# LKS32MC07x register map
Vendor: Linko Ltd.; Series: LKS32MC07x; File version: 1.0
CPU: CM0 r1p0, little endian, MPU, no FPU, 3 interrupt priority bits
Registers are 32-bit, read-write, reset 0x0 unless marked. A register's access mark holds for its fields unless they carry their own. Offsets are from the block's base; [hi:lo] are bit positions; {n}, {i} and the like mark numbered series.

## MCPWM0 — MCPWM0 registers
Base 0x40010C00
0x00 TH00 — CH0 P 16-bit Threshold Value
  [15:0] TH00 — Channel0 P-side threshold
0x04 TH01 — CH0 N 16-bit Threshold Value
  [15:0] TH01 — Channel0 N-side threshold
0x08 TH10 — CH1 P 16-bit Threshold Value
  [15:0] TH10 — Channel1 P-side threshold
0x0C TH11 — CH1 N 16-bit Threshold Value
  [15:0] TH11 — Channel1 N-side threshold
0x10 TH20 — CH2 P 16-bit Threshold Value
  [15:0] TH20 — Channel2 P-side threshold
0x14 TH21 — CH2 N 16-bit Threshold Value
  [15:0] TH21 — Channel2 N-side threshold
0x18 TH30 — CH3 P 16-bit Threshold Value
  [15:0] TH30 — Channel3 P-side threshold
0x1C TH31 — CH3 N 16-bit Threshold Value
  [15:0] TH31 — Channel3 N-side threshold
0x20 TH40 — CH4 P 16-bit Threshold Value
  [15:0] TH40 — Channel4 P-side threshold
0x24 TH41 — CH4 N 16-bit Threshold Value
  [15:0] TH41 — Channel4 N-side threshold
0x28 TH50 — CH5 P 16-bit Threshold Value
  [15:0] TH50 — Channel5 P-side threshold
0x2C TH51 — CH5 N 16-bit Threshold Value
  [15:0] TH51 — Channel5 N-side threshold
{0x30+4i} TMR{i} reset 0x7FFF (i=0..3) — ADC Trigger time {i}
  [15:0] TMR{i} — ADC Trigger time {i} counter value
0x40 TH0 — Base Counter 0 15-bit Unsigned Threshold Value
  [14:0] TH0 — MCPWM Counter 0 TH
0x44 TH1 — Base Counter 1 15-bit Unsigned Threshold Value
  [14:0] TH1 — MCPWM Counter 1 TH
0x48 CNT0 — Base 0 Counter 16-bit Signed Threshold Value
  [15:0] CNT0 — MCPWM Counter 0 Value
0x4C CNT1 — Base 1 Counter 16-bit Signed Value
  [15:0] CNT1 — MCPWM Counter 1 Value
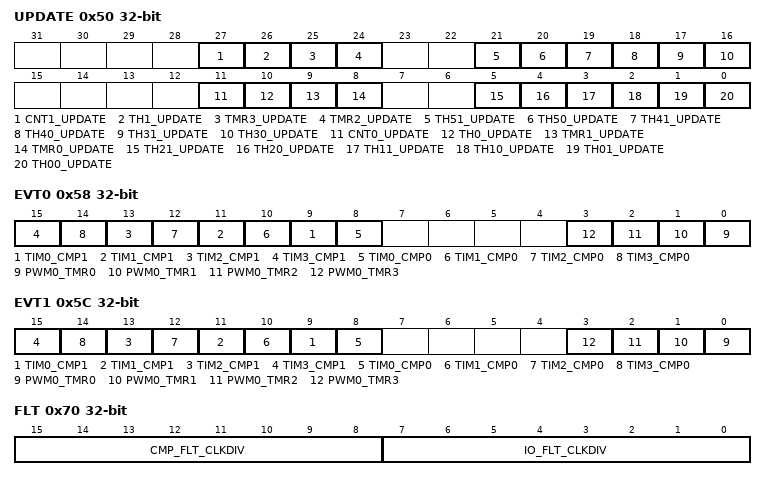
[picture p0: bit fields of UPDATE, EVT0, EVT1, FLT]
0x50 UPDATE wo (reset mask 0xFFFF) — Mask Registers Manual Reload Configuration
  [27] CNT1_UPDATE — Write 1 to trigger CNT1 update immediately
  [26] TH1_UPDATE — Write 1 to trigger TH1 update immediately
  [25] TMR3_UPDATE — Write 1 to trigger TMR3 update immediately
  [24] TMR2_UPDATE — Write 1 to trigger TMR2 update immediately
  [21] TH51_UPDATE — Write 1 to trigger TH51 update immediately
  [20] TH50_UPDATE — Write 1 to trigger TH50 update immediately
  [19] TH41_UPDATE — Write 1 to trigger TH41 update immediately
  [18] TH40_UPDATE — Write 1 to trigger TH40 update immediately
  [17] TH31_UPDATE — Write 1 to trigger TH31 update immediately
  [16] TH30_UPDATE — Write 1 to trigger TH30 update immediately
  [11] CNT0_UPDATE — Write 1 to trigger CNT0 update immediately
  [10] TH0_UPDATE — Write 1 to trigger TH0 update immediately
  [9] TMR1_UPDATE — Write 1 to trigger TMR1 update immediately
  [8] TMR0_UPDATE — Write 1 to trigger TMR0 update immediately
  [5] TH21_UPDATE — Write 1 to trigger TH21 update immediately
  [4] TH20_UPDATE — Write 1 to trigger TH20 update immediately
  [3] TH11_UPDATE — Write 1 to trigger TH11 update immediately
  [2] TH10_UPDATE — Write 1 to trigger TH10 update immediately
  [1] TH01_UPDATE — Write 1 to trigger TH01 update immediately
  [0] TH00_UPDATE — Write 1 to trigger TH00 update immediately
0x54 FCNT — If MCPWM_FAIL012[15] = 1, when fail0/1 occure, store MCPWM_CNT0 to MCPWM_FCNT. If MCPWM_FAIL3[15] = 1, when fail2/3 occure, store MCPWM_CNT0 to MCPWM_FCNT.
  [15:0] FCNT — Counter Value when failure event happens
0x58 EVT0 (reset mask 0xF0F) — MCPWM Base 0 External Trigger Register
  [2n+9] TIM{n}_CMP1 (n=0..3) — TIMER{n} CMP1 base 0 Trigger
  [2n+8] TIM{n}_CMP0 (n=0..3) — TIMER{n} CMP0 base 0 Trigger
  [n] PWM0_TMR{n} (n=0..3) — MCPWM0 TMR{n} base 0 Trigger
0x5C EVT1 (reset mask 0xF0F) — MCPWM Base 1 External Trigger Register
  [2n+9] TIM{n}_CMP1 (n=0..3) — TIMER{n} CMP1 base 1 Trigger
  [2n+8] TIM{n}_CMP0 (n=0..3) — TIMER{n} CMP0 base 1 Trigger
  [n] PWM0_TMR{n} (n=0..3) — MCPWM0 TMR{n} base 1 Trigger
0x60 DTH00 — Channel0/1/2 N Dead Zone Control Register, 10-bit Unsigned
  [9:0] DTH00
0x64 DTH01 — Channel0/1/2 P Dead Zone Control Register, 10-bit Unsigned
  [9:0] DTH01
0x68 DTH10 — Channel3/4/5 N Dead Zone Control Register, 10-bit Unsigned
  [9:0] DTH10
0x6C DTH11 — Channel3/4/5 P Dead Zone Control Register, 10-bit Unsigned
  [9:0] DTH11
0x70 FLT — FAIL signal filter config
  [15:8] CMP_FLT_CLKDIV — Clock Source is System Clock, Divide Range is 1 to 256
  [7:0] IO_FLT_CLKDIV — Clock Source is System Clock, Divide Range is 1 to 256
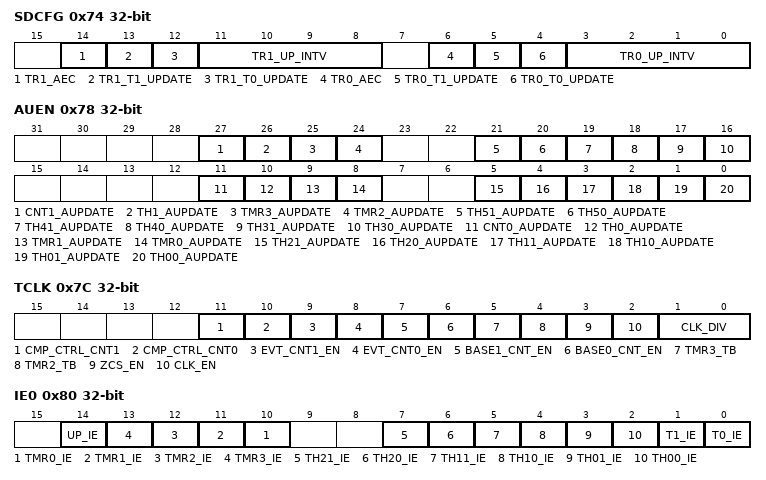
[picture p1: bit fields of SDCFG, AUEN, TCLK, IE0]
0x74 SDCFG — Shadow Registers Reload Configuration
  [14] TR1_AEC — Set MCPWM_FAIL3.MOE upon update events or not
  [13] TR1_T1_UPDATE — Update counter1 based shadow registers @ T1 event
  [12] TR1_T0_UPDATE — Update counter1 based shadow registers @ T0 event
  [11:8] TR1_UP_INTV — Counter1 based Shadow Register Auto Update Interval
  [6] TR0_AEC — Set MCPWM_FAIL012.MOE upon update events or not
  [5] TR0_T1_UPDATE — Update counter0 based shadow registers @ T1 event
  [4] TR0_T0_UPDATE — Update counter0 based shadow registers @ T0 event
  [3:0] TR0_UP_INTV — Counter0 based Shadow Register Auto Update Interval
0x78 AUEN (reset mask 0xFFFF) — Auto update enable
  [27] CNT1_AUPDATE — MCPWM_CNT1 auto update enable
  [26] TH1_AUPDATE — MCPWM_TH1 auto update enable
  [25] TMR3_AUPDATE — MCPWM_TMR3 auto update enable
  [24] TMR2_AUPDATE — MCPWM_TMR2 auto update enable
  [21] TH51_AUPDATE — MCPWM_TH51 auto update enable
  [20] TH50_AUPDATE — MCPWM_TH50 auto update enable
  [19] TH41_AUPDATE — MCPWM_TH41 auto update enable
  [18] TH40_AUPDATE — MCPWM_TH40 auto update enable
  [17] TH31_AUPDATE — MCPWM_TH31 auto update enable
  [16] TH30_AUPDATE — MCPWM_TH30 auto update enable
  [11] CNT0_AUPDATE — MCPWM_CNT0 auto update enable
  [10] TH0_AUPDATE — MCPWM_TH0 auto update enable
  [9] TMR1_AUPDATE — MCPWM_TMR1 auto update enable
  [8] TMR0_AUPDATE — MCPWM_TMR0 auto update enable
  [5] TH21_AUPDATE — MCPWM_TH21 auto update enable
  [4] TH20_AUPDATE — MCPWM_TH20 auto update enable
  [3] TH11_AUPDATE — MCPWM_TH11 auto update enable
  [2] TH10_AUPDATE — MCPWM_TH10 auto update enable
  [1] TH01_AUPDATE — MCPWM_TH01 auto update enable
  [0] TH00_AUPDATE — MCPWM_TH00 auto update enable
0x7C TCLK — MCPWM Clock Configuration Register
  [11] CMP_CTRL_CNT1 — CMP contrl MCPWM_CNT1
  [10] CMP_CTRL_CNT0 — CMP contrl MCPWM_CNT0
  [9] EVT_CNT1_EN — Base Counter1 external trigger enable
  [8] EVT_CNT0_EN — Base Counter0 external trigger enable
  [7] BASE1_CNT_EN — Base Counter1 Enable
  [6] BASE0_CNT_EN — Base Counter0 Enable
  [5] TMR3_TB — TMR3 base counter select
    0=CNT0 (Base Counter0); 1=CNT1 (Base Counter1)
  [4] TMR2_TB — TMR2 base counter select
    0=CNT0 (Base Counter0); 1=CNT1 (Base Counter1)
  [3] ZCS_EN — ZCS delay enable
  [2] CLK_EN — Module Clock Enable or Not
  [1:0] CLK_DIV — Module Clock Divider Setting, Clock Source is System Clock
    0=DIV1 (Main clock is not divided); 1=DIV2 (Main clock is divided by 2); 2=DIV4 (Main clock is divided by 4); 3=DIV8 (Main clock is divided by 8)
0x80 IE0 — Counter0 based Interrupt Sources Enable
  [14] UP_IE — Shade Register Update Interrupt Enable
  [n+10] TMR{n}_IE (n=0..3) — Counter0 is equal to TMR{n} Interrupt Enable
  [7] TH21_IE — Counter0 is equal to TH21 Interrupt Enable
  [6] TH20_IE — Counter0 is equal to TH20 Interrupt Enable
  [5] TH11_IE — Counter0 is equal to TH11 Interrupt Enable
  [4] TH10_IE — Counter0 is equal to TH10 Interrupt Enable
  [3] TH01_IE — Counter0 is equal to TH01 Interrupt Enable
  [2] TH00_IE — Counter0 is equal to TH00 Interrupt Enable
  [1] T1_IE — Counter0 is equal to 0 Interrupt Enable
  [0] T0_IE — Counter0 Return to -TH Interrupt Enable
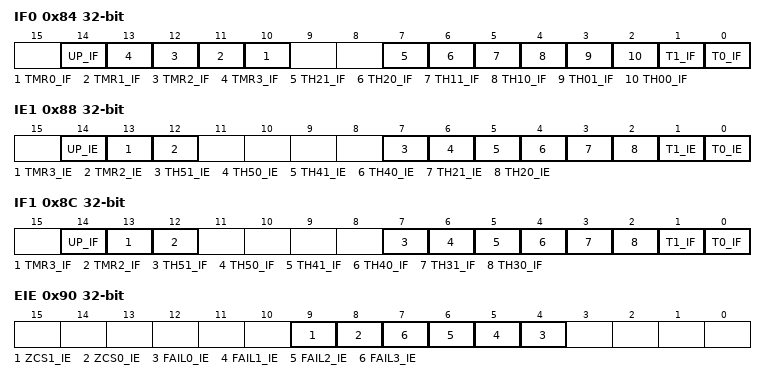
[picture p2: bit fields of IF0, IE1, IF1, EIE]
0x84 IF0 — Counter0 based Interrupt Flags
  [14] UP_IF — Shade Register Update Interrupt Flag
  [n+10] TMR{n}_IF (n=0..3) — TMR{n} Interrupt Flag,Counter0 is equal to TMR{n}
  [7] TH21_IF — TH21 Interrupt Flag,Counter0 is equal to TH21
  [6] TH20_IF — TH20 Interrupt Flag,Counter0 is equal to TH20
  [5] TH11_IF — TH11 Interrupt Flag,Counter0 is equal to TH11
  [4] TH10_IF — TH10 Interrupt Flag,Counter0 is equal to TH10
  [3] TH01_IF — TH01 Interrupt Flag,Counter0 is equal to TH01
  [2] TH00_IF — TH00 Interrupt Flag,Counter0 is equal to TH00
  [1] T1_IF — T1 Interrupt Flag,Counter0 Return to -TH
  [0] T0_IF — T0 Interrupt Flag,Counter0 Return to -TH
0x88 IE1 — Counter1 based Interrupt Sources Enable
  [14] UP_IE — Shade Register Update Interrupt Enable
  [13] TMR3_IE — Counter1 is equal to TMR3 Interrupt Enable
  [12] TMR2_IE — Counter1 is equal to TMR2 Interrupt Enable
  [7] TH51_IE — Counter1 is equal to TH51 Interrupt Enable
  [6] TH50_IE — Counter1 is equal to TH50 Interrupt Enable
  [5] TH41_IE — Counter1 is equal to TH41 Interrupt Enable
  [4] TH40_IE — Counter1 is equal to TH40 Interrupt Enable
  [3] TH21_IE — Counter1 is equal to TH21 Interrupt Enable
  [2] TH20_IE — Counter1 is equal to TH20 Interrupt Enable
  [1] T1_IE — Counter1 is equal to 0 Interrupt Enable
  [0] T0_IE — Counter1 Return to -TH Interrupt Enable
0x8C IF1 — Counter1 based Interrupt Flags
  [14] UP_IF — Shade Register Update Interrupt Flag
  [13] TMR3_IF — TMR3 Interrupt Flag,Counter1 is equal to TMR3
  [12] TMR2_IF — TMR2 Interrupt Flag,Counter1 is equal to TMR2
  [7] TH51_IF — TH51 Interrupt Flag, when Counter1 is equal to TH51
  [6] TH50_IF — TH50 Interrupt Flag, when Counter1 is equal to TH50
  [5] TH41_IF — TH41 Interrupt Flag, when Counter1 is equal to TH41
  [4] TH40_IF — TH40 Interrupt Flag, when Counter1 is equal to TH40
  [3] TH31_IF — TH31 Interrupt Flag, when Counter1 is equal to TH31
  [2] TH30_IF — TH30 Interrupt Flag, when Counter1 is equal to TH30
  [1] T1_IF — T1 Interrupt Flag,Counter1 Return to -TH
  [0] T0_IF — T0 Interrupt Flag,Counter1 Return to -TH
0x90 EIE (reset mask 0xFF) — Error Interrupt Sources Enable
  [9] ZCS1_IE — ZCS1 Interrupt enable
  [8] ZCS0_IE — ZCS0 Interrupt enable
  [n+4] FAIL{n}_IE (n=0..3) — FAIL{n} Interrupt enable
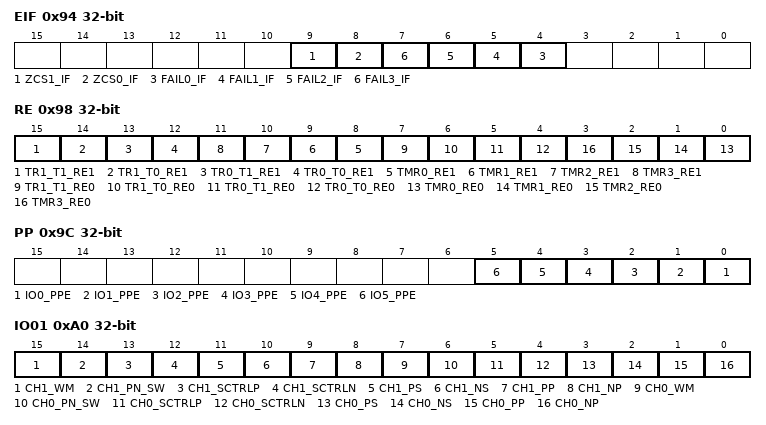
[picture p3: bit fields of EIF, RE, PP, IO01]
0x94 EIF (reset mask 0xFF) — Error Interrupt Flags
  [9] ZCS1_IF — ZCS1 Interrupt flag
  [8] ZCS0_IF — ZCS0 Interrupt flag
  [n+4] FAIL{n}_IF (n=0..3) — FAIL{n} Interrupt flag
0x98 RE (reset mask 0x3F) — DMA request enable
  [15] TR1_T1_RE1 — Counter1 Crossing Zero Event DMA request1 enable
  [14] TR1_T0_RE1 — Counter1 Start Over Event DMA request1 enable
  [13] TR0_T1_RE1 — Counter0 Crossing Zero Event DMA request1 enable
  [12] TR0_T0_RE1 — Counter0 Start Over Event DMA request1 enable
  [n+8] TMR{n}_RE1 (n=0..3) — ADC trigger {n} DMA request1 enable
  [7] TR1_T1_RE0 — Counter1 Crossing Zero Event DMA request0 enable
  [6] TR1_T0_RE0 — Counter1 Start Over Event DMA request0 enable
  [5] TR0_T1_RE0 — Counter0 Crossing Zero Event DMA request0 enable
  [4] TR0_T0_RE0 — Counter0 Start Over Event DMA request0 enable
  [n] TMR{n}_RE0 (n=0..3) — ADC trigger {n} DMA request0 enable
0x9C PP (reset mask 0xF) — Push-Pull configuration
  [n] IO{n}_PPE (n=0..5) — IO{n} Push-Pull mode enable
0xA0 IO01 — Channel 0/1 Setting
  [15] CH1_WM — Channel_1 WorkMode
  [14] CH1_PN_SW — Channel_1 P/N Switch
  [13] CH1_SCTRLP — Channel_1 SoftCtrlP
  [12] CH1_SCTRLN — Channel_1 SoftCtrlN
  [11] CH1_PS — Channel_1 P Source
  [10] CH1_NS — Channel_1 N Source
  [9] CH1_PP — Channel_1 P Polarity
  [8] CH1_NP — Channel_1 N Polarity
  [7] CH0_WM — Channel_0 WorkMode
  [6] CH0_PN_SW — Channel_0 P/N Switch
  [5] CH0_SCTRLP — Channel_0 SoftCtrlP
  [4] CH0_SCTRLN — Channel_0 SoftCtrlN
  [3] CH0_PS — Channel_0 P Source
  [2] CH0_NS — Channel_0 N Source
  [1] CH0_PP — Channel_0 P Polarity
  [0] CH0_NP — Channel_0 N Polarity
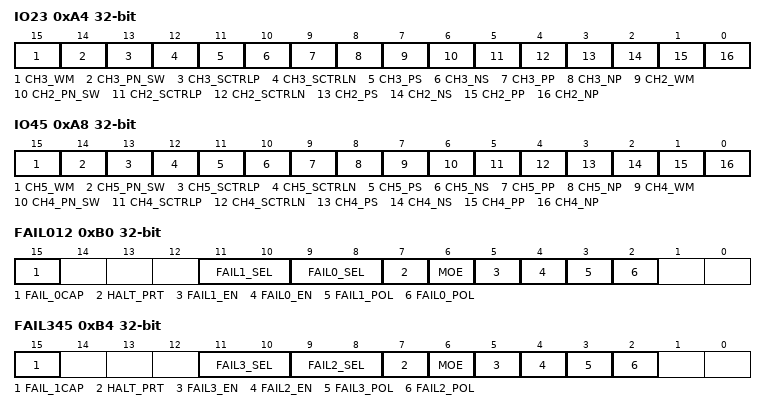
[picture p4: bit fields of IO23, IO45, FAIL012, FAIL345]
0xA4 IO23 — Channel 2/3 Setting
  [15] CH3_WM — Channel_3 WorkMode
  [14] CH3_PN_SW — Channel_3 P/N Switch
  [13] CH3_SCTRLP — Channel_3 SoftCtrlP
  [12] CH3_SCTRLN — Channel_3 SoftCtrlN
  [11] CH3_PS — Channel_3 P Source
  [10] CH3_NS — Channel_3 N Source
  [9] CH3_PP — Channel_3 P Polarity
  [8] CH3_NP — Channel_3 N Polarity
  [7] CH2_WM — Channel_2 WorkMode
  [6] CH2_PN_SW — Channel_2 P/N Switch
  [5] CH2_SCTRLP — Channel_2 SoftCtrlP
  [4] CH2_SCTRLN — Channel_2 SoftCtrlN
  [3] CH2_PS — Channel_2 P Source
  [2] CH2_NS — Channel_2 N Source
  [1] CH2_PP — Channel_2 P Polarity
  [0] CH2_NP — Channel_2 N Polarity
0xA8 IO45 — Channel 4/5 Setting
  [15] CH5_WM — Channel_5 WorkMode
  [14] CH5_PN_SW — Channel_5 P/N Switch
  [13] CH5_SCTRLP — Channel_5 SoftCtrlP
  [12] CH5_SCTRLN — Channel_5 SoftCtrlN
  [11] CH5_PS — Channel_5 P Source
  [10] CH5_NS — Channel_5 N Source
  [9] CH5_PP — Channel_5 P Polarity
  [8] CH5_NP — Channel_5 N Polarity
  [7] CH4_WM — Channel_4 WorkMode
  [6] CH4_PN_SW — Channel_4 P/N Switch
  [5] CH4_SCTRLP — Channel_4 SoftCtrlP
  [4] CH4_SCTRLN — Channel_4 SoftCtrlN
  [3] CH4_PS — Channel_4 P Source
  [2] CH4_NS — Channel_4 N Source
  [1] CH4_PP — Channel_4 P Polarity
  [0] CH4_NP — Channel_4 N Polarity
0xB0 FAIL012 — MCPWM Channel 0/1/2 Short Control Register
  [15] FAIL_0CAP — Save Counter0 to MCPWM_FCNT during fail0/1 event
  [11:10] FAIL1_SEL — Fail signal 1 select
    0=MCPWM0_BKIN1 (Use MCPWM0_BKIN1 as FAIL1); 1=CMP1_OUT (Use CMP1_OUT as FAIL1); 2=CLUOUT2 (Use CLUOUT2 as FAIL1); 3=CLUOUT3 (Use CLUOUT3 as FAIL1)
  [9:8] FAIL0_SEL — Fail signal 0 select
    0=MCPWM0_BKIN0 (Use MCPWM0_BKIN0 as FAIL0); 1=CMP0_OUT (Use CMP0_OUT as FAIL0); 2=CLUOUT0 (Use CLUOUT0 as FAIL0); 3=CLUOUT1 (Use CLUOUT1 as FAIL0)
  [7] HALT_PRT — MCU in Debug Mode(Halted by Debug), MCPWM Close or Not
  [6] MOE — MCPWM Output Enable
  [5] FAIL1_EN — FAIL 1 Short Protect Enable or Not
  [4] FAIL0_EN — FAIL 0 Short Protect Enable or Not
  [3] FAIL1_POL — FAIL 1 active polarity
    0=H (Fail Signal high active); 1=L (Fail Signal low active)
  [2] FAIL0_POL — FAIL 0 active polarity
    0=H (Fail Signal high active); 1=L (Fail Signal low active)
0xB4 FAIL345 — MCPWM Channel 3/4/5 Short Control Register
  [15] FAIL_1CAP — Save Counter1 to MCPWM_FCNT during fail2/3 event
  [11:10] FAIL3_SEL — Fail signal 3 select
    0=MCPWM0_BKIN1 (Use MCPWM0_BKIN1 as FAIL3); 1=CMP1_OUT (Use CMP1_OUT as FAIL3); 2=CLUOUT2 (Use CLUOUT2 as FAIL3); 3=CLUOUT3 (Use CLUOUT3 as FAIL3)
  [9:8] FAIL2_SEL — Fail signal 2 select
    0=MCPWM0_BKIN0 (Use MCPWM0_BKIN0 as FAIL2); 1=CMP0_OUT (Use CMP0_OUT as FAIL2); 2=CLUOUT0 (Use CLUOUT0 as FAIL2); 3=CLUOUT1 (Use CLUOUT1 as FAIL2)
  [7] HALT_PRT — MCU in Debug Mode(Halted by Debug), MCPWM Close or Not
  [6] MOE — MCPWM Output Enable
  [5] FAIL3_EN — FAIL 3 Short Protect Enable or Not
  [4] FAIL2_EN — FAIL 2 Short Protect Enable or Not
  [3] FAIL3_POL — FAIL 3 active polarity
    0=H (Fail Signal high active); 1=L (Fail Signal low active)
  [2] FAIL2_POL — FAIL 2 active polarity
    0=H (Fail Signal high active); 1=L (Fail Signal low active)
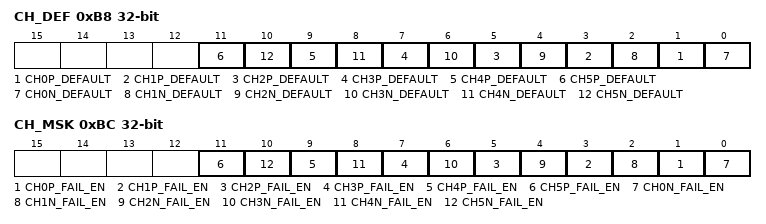
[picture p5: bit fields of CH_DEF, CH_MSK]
0xB8 CH_DEF — MCPWM Channel Default Value
  [2n+1] CH{n}P_DEFAULT (n=0..5) — CH{n}P default value
  [2n] CH{n}N_DEFAULT (n=0..5) — CH{n}N default value
0xBC CH_MSK — MCPWM Channel Fail Mask
  [2n+1] CH{n}P_FAIL_EN (n=0..5) — Set ch{n}p to default during failure event
  [2n] CH{n}N_FAIL_EN (n=0..5) — Set ch{n}n to default during failure event
0xC0 PRT wo — MCPWM Register Protection.Write 0xDEAD to unlock Protect
  [15:0] PRT
0xC8 STT_HYST — MCPWM State Hysteresis time
  [11:0] HYST_TIME — MCPWM state hysteresis time, i.e. minimum stay time in each state
0xCC ZCS_DELAY — MCPWM ZCS Delay time
  [14:0] ZCS_DELAY — MCPWM ZCS delay time when ZCS happens
